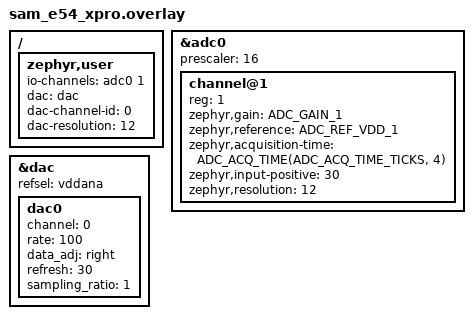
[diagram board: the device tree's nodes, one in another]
/*
 * Copyright (c) 2026 Microchip Technology Inc.
 *
 * SPDX-License-Identifier: Apache-2.0
 */

/* DAC0 internally connected to ADC channel 30*/

/ {
	zephyr,user {
		io-channels = <&adc0 1>;
		dac = <&dac>;
		dac-channel-id = <0>;
		dac-resolution = <12>;
	};
};

&adc0{
	#address-cells = <1>;
	#size-cells = <0>;
	status = "okay";
	prescaler = <16>;

	channel@1 {
		reg = <1>;
		zephyr,gain = "ADC_GAIN_1";
		zephyr,reference = "ADC_REF_VDD_1";
		zephyr,acquisition-time = <ADC_ACQ_TIME(ADC_ACQ_TIME_TICKS, 4)>;
		zephyr,input-positive = <30>;
		zephyr,resolution = <12>;
	};
};

&dac {
	status = "okay";
	refsel = "vddana";
	dac0:dac0{
		channel = <0>;
		rate = <100>;
		data_adj = "right";
		refresh = <30>;
		sampling_ratio = <1>;
	};
};
